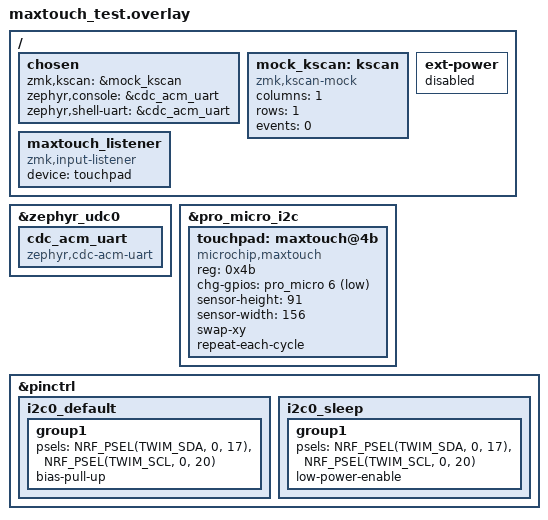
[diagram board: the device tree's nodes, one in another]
/*
 * Copyright (c) 2024 The ZMK Contributors
 * SPDX-License-Identifier: MIT
 */

#include <dt-bindings/zmk/matrix_transform.h>
#include <dt-bindings/zmk/input_transform.h>
#include <dt-bindings/pinctrl/nrf-pinctrl.h>

/ {
    chosen {
        zmk,kscan = &mock_kscan;
        zephyr,console = &cdc_acm_uart;
        zephyr,shell-uart = &cdc_acm_uart;
    };

    // Minimal mock 1-key matrix so ZMK initializes without physical switch matrix wiring
    mock_kscan: kscan {
        compatible = "zmk,kscan-mock";
        columns = <1>;
        rows = <1>;
        events = <0>;
    };

    maxtouch_listener {
        compatible = "zmk,input-listener";
        device = <&touchpad>;
    };

    ext-power {
        status = "disabled";
    };
};

&zephyr_udc0 {
    cdc_acm_uart: cdc_acm_uart {
        compatible = "zephyr,cdc-acm-uart";
    };
};

&pro_micro_i2c {
    status = "okay";

    touchpad: maxtouch@4b {
        reg = <0x4b>;
        compatible = "microchip,maxtouch";
        chg-gpios = <&pro_micro 6 (GPIO_ACTIVE_LOW | GPIO_PULL_UP)>;
        sensor-height = <91>;
        sensor-width = <156>;
        swap-xy;
        repeat-each-cycle;
    };
};

&pinctrl {
    i2c0_default: i2c0_default {
        group1 {
            psels = <NRF_PSEL(TWIM_SDA, 0, 17)>,
                    <NRF_PSEL(TWIM_SCL, 0, 20)>;
            bias-pull-up;
        };
    };

    i2c0_sleep: i2c0_sleep {
        group1 {
            psels = <NRF_PSEL(TWIM_SDA, 0, 17)>,
                    <NRF_PSEL(TWIM_SCL, 0, 20)>;
            low-power-enable;
        };
    };
};
